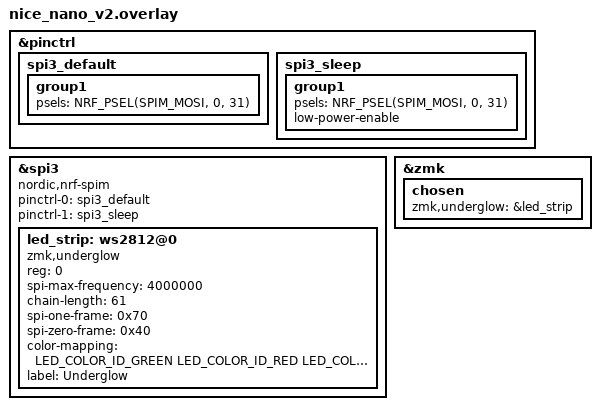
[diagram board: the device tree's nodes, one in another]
#include <dt-bindings/led/led.h>

/* Configuração dos pinos SPI */
&pinctrl {
    spi3_default: spi3_default {
        group1 {
            psels = <NRF_PSEL(SPIM_MOSI, 0, 31)>;  // LED data pin
        };
    };

    spi3_sleep: spi3_sleep {
        group1 {
            psels = <NRF_PSEL(SPIM_MOSI, 0, 31)>;
            low-power-enable; // Ativa modo de baixo consumo
        };
    };
};

/* Configuração do dispositivo SPI */
&spi3 {
    compatible = "nordic,nrf-spim";
    status = "okay";

    pinctrl-0 = <&spi3_default>;
    pinctrl-1 = <&spi3_sleep>;
    pinctrl-names = "default", "sleep";

    /* Nó do strip de LEDs WS2812 */
    led_strip: ws2812@0 {
        compatible = "worldsemi,ws2812-spi";
        reg = <0>; /* Requerido pelo binding do SPI */
        spi-max-frequency = <4000000>;

        chain-length = <61>; // Número total de LEDs
        spi-one-frame = <0x70>;
        spi-zero-frame = <0x40>;

        color-mapping = <LED_COLOR_ID_GREEN
                         LED_COLOR_ID_RED
                         LED_COLOR_ID_BLUE>;
    };
};

/* Informa ao ZMK que este é o underglow controlado */
&led_strip {
    compatible = "zmk,underglow";
    label = "Underglow";
};

/* Liga o underglow no teclado */
&zmk {
    chosen {
        zmk,underglow = &led_strip;
    };
};
